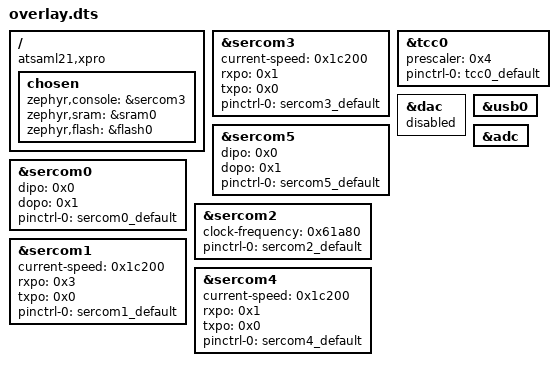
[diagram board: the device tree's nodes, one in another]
/ {
	compatible = "atsaml21,xpro", "atmel,saml21j18b", "atmel,saml21";
	chosen {
		zephyr,console = &sercom3;
		zephyr,sram = &sram0;
		zephyr,flash = &flash0;
	};
};
&sercom3{
	status = "okay";
	current-speed = < 0x1c200 >;
	rxpo = < 0x1 >;
	txpo = < 0x0 >;
	pinctrl-0 = < &sercom3_default >;
	pinctrl-names = "default";
};
&sercom5{
	status = "okay";
	dipo = < 0x0 >;
	dopo = < 0x1 >;
	#address-cells = < 0x1 >;
	#size-cells = < 0x0 >;
	pinctrl-0 = < &sercom5_default >;
	pinctrl-names = "default";
};
&tcc0{
	status = "okay";
	prescaler = < 0x4 >;
	#pwm-cells = < 0x2 >;
	pinctrl-0 = < &tcc0_default >;
	pinctrl-names = "default";
};
&sercom0{
	status = "okay";
	dipo = < 0x0 >;
	dopo = < 0x1 >;
	#address-cells = < 0x1 >;
	#size-cells = < 0x0 >;
	pinctrl-0 = < &sercom0_default >;
	pinctrl-names = "default";
};
&sercom2{
	status = "okay";
	clock-frequency = < 0x61a80 >;
	#address-cells = < 0x1 >;
	#size-cells = < 0x0 >;
	pinctrl-0 = < &sercom2_default >;
	pinctrl-names = "default";
};
&sercom1{
	status = "okay";
	current-speed = < 0x1c200 >;
	rxpo = < 0x3 >;
	txpo = < 0x0 >;
	pinctrl-0 = < &sercom1_default >;
	pinctrl-names = "default";
};
&dac{
	status = "disabled";
};
&usb0{
	status = "okay";
};
&sercom4{
	status = "okay";
	current-speed = < 0x1c200 >;
	rxpo = < 0x1 >;
	txpo = < 0x0 >;
	pinctrl-0 = < &sercom4_default >;
	pinctrl-names = "default";
};
&adc{
	status = "okay";
};
